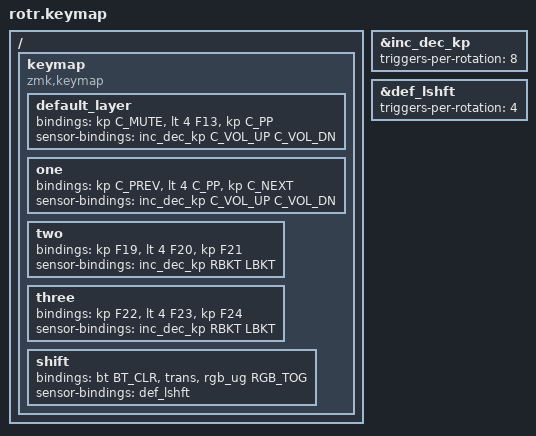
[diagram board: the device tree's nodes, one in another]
#include <behaviors.dtsi>
#include <dt-bindings/zmk/keys.h>
#include <dt-bindings/zmk/rgb.h>
#include <dt-bindings/zmk/bt.h>

&inc_dec_kp {
	triggers-per-rotation = <8>;
};
&def_lshft {
	triggers-per-rotation = <4>;
};

/ {
	keymap {
		compatible = "zmk,keymap";

		default_layer {
			//PREV | PLAY/PAUSE | NEXT
			bindings = <&kp C_MUTE &lt 4 F13 &kp C_PP>;
			sensor-bindings = <&inc_dec_kp C_VOL_UP C_VOL_DN>;
		};
		one {
			//New Layer| Delete Layer | NEXT
			bindings = <&kp C_PREV &lt 4 C_PP &kp C_NEXT>;
			sensor-bindings = <&inc_dec_kp C_VOL_UP C_VOL_DN>;
		};
		two {
			//Generic Function Keys 19 to 21
			bindings = <&kp F19 &lt 4 F20 &kp F21>;
			sensor-bindings = <&inc_dec_kp RBKT LBKT>;
		};
		three {
			//Generic Function Keys 22 to 24
			bindings = <&kp F22 &lt 4 F23 &kp F24>;
			sensor-bindings = <&inc_dec_kp RBKT LBKT>;
		};
		shift {
			//PREV | PLAY/PAUSE | NEXT
			bindings = <&bt BT_CLR &trans &rgb_ug RGB_TOG>;
			sensor-bindings = <&def_lshft>;
		};
	};
};
